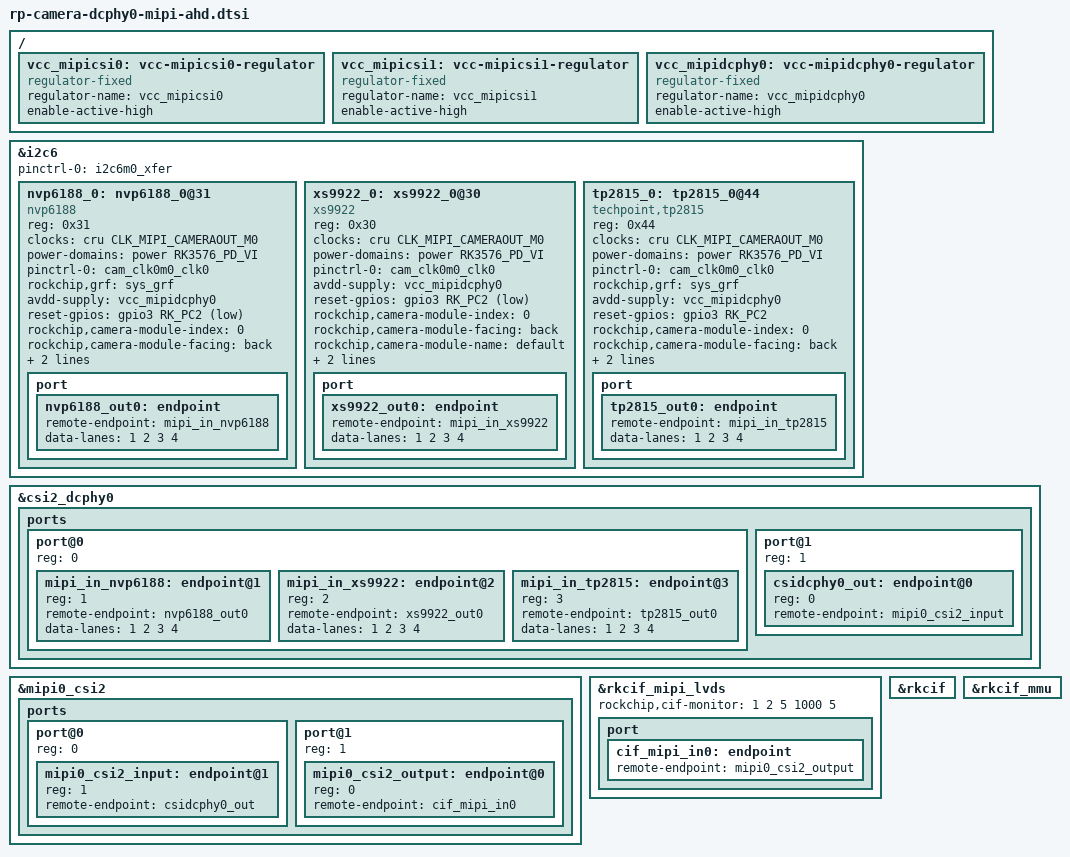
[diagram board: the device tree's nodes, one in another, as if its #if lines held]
/*
 * xs9922_0 -> MIPI_DPHY0 -> mipi_dcphy0 -> mipi0_csi2 -> cif0
 */

/{
    vcc_mipicsi0: vcc-mipicsi0-regulator {
        compatible = "regulator-fixed";
        regulator-name = "vcc_mipicsi0";
        enable-active-high;
    };

    vcc_mipicsi1: vcc-mipicsi1-regulator {
        compatible = "regulator-fixed";
        regulator-name = "vcc_mipicsi1";
        enable-active-high;
    };

    vcc_mipidcphy0: vcc-mipidcphy0-regulator {
        compatible = "regulator-fixed";
        regulator-name = "vcc_mipidcphy0";
        enable-active-high;
    };
};


&i2c6 {
    status = "okay";
    pinctrl-names = "default";
    pinctrl-0 = <&i2c6m0_xfer>;
	
    nvp6188_0: nvp6188_0@31 {
        reg = <0x31>;
        compatible = "nvp6188";
        status = "okay";
        clocks = <&cru CLK_MIPI_CAMERAOUT_M0>;
        clock-names = "xvclk";
        power-domains = <&power RK3576_PD_VI>;
        pinctrl-names = "default";
        pinctrl-0 = <&cam_clk0m0_clk0>;
		rockchip,grf = <&sys_grf>;
        avdd-supply = <&vcc_mipidcphy0>;
		
#if defined RP_RK3576S || defined PRO_RK3576X
        reset-gpios = <&gpio3 RK_PC2 GPIO_ACTIVE_LOW>;
        //power-gpios = <&nca9555_gpio IO_01 GPIO_ACTIVE_HIGH>;
#elif defined  DR4_RK3576X
        reset-gpios = <&gpio3 RK_PC2 GPIO_ACTIVE_LOW>;
        //power-gpios = <&nca9555_gpio IO_01 GPIO_ACTIVE_HIGH>;
#elif defined  PRO_RK3576_MID
        reset-gpios = <&gpio4 RK_PA6 GPIO_ACTIVE_LOW>;
        //power-gpios = <&nca9555_gpio IO_01 GPIO_ACTIVE_HIGH>;
#else  //rk3576
        reset-gpios = <&nca9555_gpio IO_00 GPIO_ACTIVE_LOW>;
        //power-gpios = <&nca9555_gpio IO_01 GPIO_ACTIVE_HIGH>;
#endif        

        //avdd-supply = <&vcc_avdd>;
        //dovdd-supply = <&vcc_dovdd>;
        //dvdd-supply = <&vcc_dvdd>;
        rockchip,camera-module-index = <0>;
        rockchip,camera-module-facing = "back";
        rockchip,camera-module-name = "nvp6188";
        rockchip,camera-module-lens-name = "nvp6188";
        port {
            nvp6188_out0: endpoint {
                remote-endpoint = <&mipi_in_nvp6188>;
                data-lanes = <1 2 3 4>;
            };
        };
    };
    
#ifdef PRO_RK3576_VIDEO
    xs9922_0: xs9922_0@30 {
        reg = <0x30>;
#else
    xs9922_0: xs9922_0@31 {
        reg = <0x31>;
#endif
        compatible = "xs9922";
        status = "okay";
        clocks = <&cru CLK_MIPI_CAMERAOUT_M0>;
        clock-names = "xvclk";
        power-domains = <&power RK3576_PD_VI>;
        pinctrl-names = "default";
        pinctrl-0 = <&cam_clk0m0_clk0>;
		avdd-supply = <&vcc_mipidcphy0>;
		
#if defined RP_RK3576S || defined PRO_RK3576X
        reset-gpios = <&gpio3 RK_PC2 GPIO_ACTIVE_LOW>;
        //power-gpios = <&nca9555_gpio IO_01 GPIO_ACTIVE_HIGH>;
#elif defined  DR4_RK3576X
        reset-gpios = <&gpio3 RK_PC2 GPIO_ACTIVE_LOW>;
        //power-gpios = <&nca9555_gpio IO_01 GPIO_ACTIVE_HIGH>;
#elif defined  PRO_RK3576_MID
        reset-gpios = <&gpio4 RK_PA6 GPIO_ACTIVE_LOW>;
        //power-gpios = <&nca9555_gpio IO_01 GPIO_ACTIVE_HIGH>;
#else  //rk3576
        reset-gpios = <&nca9555_gpio IO_00 GPIO_ACTIVE_LOW>;
        //power-gpios = <&nca9555_gpio IO_01 GPIO_ACTIVE_HIGH>;
#endif        

        //avdd-supply = <&vcc_avdd>;
        //dovdd-supply = <&vcc_dovdd>;
        //dvdd-supply = <&vcc_dvdd>;
        rockchip,camera-module-index = <0>;
        rockchip,camera-module-facing = "back";
        rockchip,camera-module-name = "default";
        rockchip,camera-module-lens-name = "default";
        rockchip,default_rect= <1280 720>; 
        port {
            xs9922_out0: endpoint {
                remote-endpoint = <&mipi_in_xs9922>;
                data-lanes = <1 2 3 4>;
            };
        };
    };
    
    
    tp2815_0: tp2815_0@44 {
        reg = <0x44>;
        compatible = "techpoint,tp2815";
        status = "okay";
        clocks = <&cru CLK_MIPI_CAMERAOUT_M0>;
        clock-names = "xvclk";
        power-domains = <&power RK3576_PD_VI>;
        pinctrl-names = "default";
        pinctrl-0 = <&cam_clk0m0_clk0>;
		rockchip,grf = <&sys_grf>;
        avdd-supply = <&vcc_mipidcphy0>;
		
#if defined RP_RK3576S || defined PRO_RK3576X
        reset-gpios = <&gpio3 RK_PC2 GPIO_ACTIVE_HIGH>;
        //power-gpios = <&nca9555_gpio IO_01 GPIO_ACTIVE_HIGH>;
#elif defined  DR4_RK3576X
        reset-gpios = <&gpio3 RK_PC2 GPIO_ACTIVE_HIGH>;
        //power-gpios = <&nca9555_gpio IO_01 GPIO_ACTIVE_HIGH>;
#elif defined  PRO_RK3576_MID
        reset-gpios = <&gpio4 RK_PA6 GPIO_ACTIVE_HIGH>;
        //power-gpios = <&nca9555_gpio IO_01 GPIO_ACTIVE_HIGH>;
#else  //rk3576
        reset-gpios = <&nca9555_gpio IO_00 GPIO_ACTIVE_HIGH>;
        //power-gpios = <&nca9555_gpio IO_01 GPIO_ACTIVE_HIGH>;
#endif        

        //avdd-supply = <&vcc_avdd>;
        //dovdd-supply = <&vcc_dovdd>;
        //dvdd-supply = <&vcc_dvdd>;
        rockchip,camera-module-index = <0>;
        rockchip,camera-module-facing = "back";
        rockchip,camera-module-name = "tp2815";
        rockchip,camera-module-lens-name = "tp2815";
        port {
            tp2815_out0: endpoint {
                remote-endpoint = <&mipi_in_tp2815>;
                data-lanes = <1 2 3 4>;
            };
        };
    };
};
// CIF
&csi2_dcphy0 {
    status = "okay";

    ports {
        #address-cells = <1>;
        #size-cells = <0>;
        port@0 {
            reg = <0>;
            #address-cells = <1>;
            #size-cells = <0>;

            mipi_in_nvp6188: endpoint@1 {
                reg = <1>;
                remote-endpoint = <&nvp6188_out0>;
                data-lanes = <1 2 3 4>;
            };
	    
            mipi_in_xs9922: endpoint@2 {
                reg = <2>;
                remote-endpoint = <&xs9922_out0>;
                data-lanes = <1 2 3 4>;
            };
            
            mipi_in_tp2815: endpoint@3 {
                reg = <3>;
                remote-endpoint = <&tp2815_out0>;
                data-lanes = <1 2 3 4>;
            };
        };
        port@1 {
            reg = <1>;
            #address-cells = <1>;
            #size-cells = <0>;

            csidcphy0_out: endpoint@0 {
                reg = <0>;
                remote-endpoint = <&mipi0_csi2_input>;
            };
        };
    };
};


&mipi0_csi2 {
    status = "okay";

    ports {
        #address-cells = <1>;
        #size-cells = <0>;

        port@0 {
            reg = <0>;
            #address-cells = <1>;
            #size-cells = <0>;

            mipi0_csi2_input: endpoint@1 {
                reg = <1>;
                remote-endpoint = <&csidcphy0_out>;
            };
        };

        port@1 {
            reg = <1>;
            #address-cells = <1>;
            #size-cells = <0>;

            mipi0_csi2_output: endpoint@0 {
                reg = <0>;
                remote-endpoint = <&cif_mipi_in0>;
            };
        };
    };
};


&rkcif_mipi_lvds {
    status = "okay";
    rockchip,cif-monitor = <1 2 5 1000 5>;
    port {
        cif_mipi_in0: endpoint {
            remote-endpoint = <&mipi0_csi2_output>;
        };
    };
};

&rkcif {
    status = "okay";
};

&rkcif_mmu {
    status = "okay";
};

#if 0
&rkcif_mipi_lvds_sditf {
	status = "okay";

	port {
		mipi_lvds_sditf: endpoint {
			remote-endpoint = <&isp_vir0_in0>;
		};
	};
};

&rkisp {
	status = "okay";
};

&rkisp_mmu {
	status = "okay";
};

&rkisp_vir0 {
	status = "okay";

	port {
		#address-cells = <1>;
		#size-cells = <0>;

		isp_vir0_in0: endpoint@0 {
			reg = <0>;
			remote-endpoint = <&mipi_lvds_sditf>;
		};
	};
};
&rkisp_vir0_sditf {
    status = "okay";
};

&rkvpss {
    status = "okay";
};

&rkvpss_mmu {
    status = "okay";
};

&rkvpss_vir0 {
    status = "okay";
};
#endif

#if 0

// isp
&mipi0_csi2 {
    status = "okay";

    ports {
        #address-cells = <1>;
        #size-cells = <0>;

        port@0 {
            reg = <0>;
            #address-cells = <1>;
            #size-cells = <0>;

            mipi0_csi2_input: endpoint@1 {
                reg = <1>;
                remote-endpoint = <&csidcphy0_out>;
            };
        };

        port@1 {
            reg = <1>;
            #address-cells = <1>;
            #size-cells = <0>;

            mipi2_csi2_output: endpoint@0 {
                reg = <0>;
                remote-endpoint = <&cif_mipi_in2>;
            };
        };
    };
};


&rkcif_mipi_lvds2 {
    status = "disabled";
    port {
        cif_mipi_in2: endpoint {
            remote-endpoint = <&mipi2_csi2_output>;
        };
    };
};
#endif

#if 0
&rkcif_mipi_lvds2_sditf {
    status = "okay";
        port {
        mipi1_lvds_sditf: endpoint {
            remote-endpoint = <&isp0_vir0>;
        };
    };
};


&rkcif_mipi_lvds_sditf {
    status = "okay";

    port {
        mipi_lvds_sditf: endpoint {
            remote-endpoint = <&isp1_in1>;
        };
    };
};


&rkisp_unite {
    status = "okay";
};

&rkisp_unite_mmu {
    status = "okay";
};

&rkisp0_vir0 {
    status = "okay";
    /*
    * dual isp process image case
    * other rkisp hw and virtual nodes should disabled
    */
    rockchip,hw = <&rkisp_unite>;
    port {
        #address-cells = <1>;
        #size-cells = <0>;

        isp0_vir0: endpoint@1 {
            reg = <1>;
            remote-endpoint = <&mipi1_lvds_sditf>;
        };
        isp1_in1: endpoint@0 {
            reg = <0>;
            remote-endpoint = <&mipi_lvds_sditf>;
        };
    };
};
#endif
